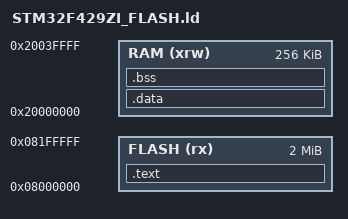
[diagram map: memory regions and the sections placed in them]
/* Minimal linker script for STM32F429ZI (FLASH) */
ENTRY(Reset_Handler)

MEMORY
{
  FLASH (rx) : ORIGIN = 0x08000000, LENGTH = 2M
  RAM (xrw)  : ORIGIN = 0x20000000, LENGTH = 256K
}

SECTIONS
{
  .text :
  {
    KEEP(*(.isr_vector))
    *(.text*)
    *(.rodata*)
    _etext = .;
  } > FLASH

  .data : AT (_etext)
  {
    _sdata = .;
    *(.data*)
    _edata = .;
  } > RAM

  .bss :
  {
    _sbss = .;
    *(.bss*)
    *(COMMON)
    _ebss = .;
  } > RAM
}
